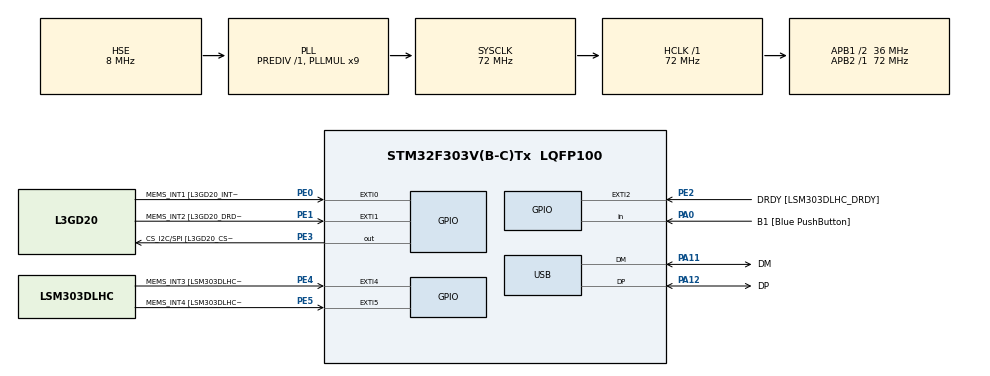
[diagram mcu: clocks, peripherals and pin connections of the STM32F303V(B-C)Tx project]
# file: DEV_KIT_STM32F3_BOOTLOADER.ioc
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Mcu.Family=STM32F3
Mcu.Name=STM32F303V(B-C)Tx
Mcu.Package=LQFP100
NVIC.PriorityGroup=NVIC_PRIORITYGROUP_0
PA0.GPIO_Label=B1 [Blue PushButton]
PA0.Signal=GPIO_Input
PA11.GPIO_Label=DM
PA11.Mode=Device
PA11.Signal=USB_DM
PA12.GPIO_Label=DP
PA12.Mode=Device
PA12.Signal=USB_DP
PA13.GPIO_Label=SWDIO
PA13.Mode=Serial_Wire
PA13.Signal=SYS_JTMS-SWDIO
PA14.GPIO_Label=SWCLK
PA14.Mode=Serial_Wire
PA14.Signal=SYS_JTCK-SWCLK
PA5.GPIO_Label=SPI1_SCK [L3GD20_SCL/SPC]
PA5.Signal=SPI1_SCK
PA6.GPIO_Label=SPI1_MISO [L3GD20_SA0/SDO]
PA6.Signal=SPI1_MISO
PA7.GPIO_Label=SPI1_MISO [L3GD20_SDA/SDI/SDO]
PA7.Signal=SPI1_MOSI
PB3.GPIO_Label=SWO
PB3.Signal=SYS_JTDO-TRACESWO
PB6.GPIO_Label=I2C1_SCL [LSM303DLHC_SCL]
PB6.GPIO_Pu=GPIO_PULLUP
PB6.Signal=I2C1_SCL
PB7.GPIO_Label=I2C1_SDA [LSM303DLHC_SDA]
PB7.GPIO_Pu=GPIO_PULLUP
PB7.Signal=I2C1_SDA
PC14-OSC32_IN.GPIO_Label=OSC32_IN
PC14-OSC32_IN.Signal=RCC_OSC32_IN
PC15-OSC32_OUT.GPIO_Label=OSC32_OUT
PC15-OSC32_OUT.Signal=RCC_OSC32_OUT
PE0.GPIO_Label=MEMS_INT1 [L3GD20_INT1]
PE0.GPIO_ModeDefaultEXTI=GPIO_MODE_EVT_RISING
PE0.Signal=GPXTI0
PE1.GPIO_Label=MEMS_INT2 [L3GD20_DRDY/INT2]
PE1.GPIO_ModeDefaultEXTI=GPIO_MODE_EVT_RISING
PE1.Signal=GPXTI1
PE2.GPIO_Label=DRDY [LSM303DLHC_DRDY]
PE2.GPIO_ModeDefaultEXTI=GPIO_MODE_EVT_RISING
PE2.Signal=GPXTI2
PE3.GPIO_Label=CS_I2C/SPI [L3GD20_CS_I2C/SPI]
PE3.Signal=GPIO_Output
PE4.GPIO_Label=MEMS_INT3 [LSM303DLHC_INT1]
PE4.GPIO_ModeDefaultEXTI=GPIO_MODE_EVT_RISING
PE4.Signal=GPXTI4
PE5.GPIO_Label=MEMS_INT4 [LSM303DLHC_INT2]
PE5.GPIO_ModeDefaultEXTI=GPIO_MODE_EVT_RISING
PE5.Signal=GPXTI5
PF0-OSC_IN.GPIO_Label=OSC_IN
PF0-OSC_IN.Mode=HSE-External-Clock-Source
PF0-OSC_IN.Signal=RCC_OSC_IN
PF1-OSC_OUT.GPIO_Label=OSC_OUT
PF1-OSC_OUT.Signal=RCC_OSC_OUT
ProjectManager.HeapSize=0x200
ProjectManager.StackSize=0x400
ProjectManager.TargetToolchain=STM32CubeIDE
RCC.AHBFreq_Value=72000000
RCC.APB1CLKDivider=RCC_HCLK_DIV2
RCC.APB1Freq_Value=36000000
RCC.APB1TimFreq_Value=72000000
RCC.APB2Freq_Value=72000000
RCC.APB2TimFreq_Value=72000000
RCC.CortexFreq_Value=72000000
RCC.HCLKFreq_Value=72000000
RCC.HSE_VALUE=8000000
RCC.HSI_VALUE=8000000
RCC.LSE_VALUE=32768
RCC.PLLMUL=RCC_PLL_MUL9
RCC.PRESCALERUSB=RCC_USBCLKSOURCE_PLL_DIV1_5
RCC.SYSCLKFreq_VALUE=72000000
RCC.SYSCLKSourceVirtual=RCC_SYSCLKSOURCE_PLLCLK
RCC.USBFreq_Value=48000000
VP_RTC_VS_RTC_Activate.Mode=RTC_Enabled
VP_RTC_VS_RTC_WakeUp_intern.Mode=WakeUp
board=STM32F3DISCOVERY

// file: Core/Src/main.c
/* USER CODE BEGIN Header */
/**
  ******************************************************************************
  * @file           : main.c
  * @brief          : Main program body
  ******************************************************************************
  * @attention
  *
  * Copyright (c) 2023 STMicroelectronics.
  * All rights reserved.
  *
  * This software is licensed under terms that can be found in the LICENSE file
  * in the root directory of this software component.
  * If no LICENSE file comes with this software, it is provided AS-IS.
  *
  ******************************************************************************
  */
/* USER CODE END Header */
#include "main.h"

RTC_HandleTypeDef hrtc;

PCD_HandleTypeDef hpcd_USB_FS;

void SystemClock_Config(void);
static void MX_GPIO_Init(void);

/* USER CODE BEGIN 0 */
void JumpToBootloader(uint32_t ADDR_FLASH_BOOT)
{
	uint32_t appStack;

	typedef void (*pFunction)(void);

	pFunction appEntry;

	appStack = (uint32_t) *((__IO uint32_t*) ADDR_FLASH_BOOT);

	/* Get the application entry point (Second entry in the application vector table) */
	appEntry = (pFunction) *(__IO uint32_t*) (ADDR_FLASH_BOOT + 4);

	/* Reconfigure vector table offset register to match the application location */
	SCB->VTOR = ADDR_FLASH_BOOT;

	/* Set the application stack pointer */
	__set_MSP(appStack);

	/* Start the application */

	appEntry();
}
/* USER CODE END 0 */

int main(void)
{

  /* MCU Configuration--------------------------------------------------------*/

  /* Reset of all peripherals, Initializes the Flash interface and the Systick. */
  HAL_Init();

  /* Configure the system clock */
  SystemClock_Config();

  /* Initialize all configured peripherals */
  MX_GPIO_Init();
  MX_USB_PCD_Init();
  MX_RTC_Init();
  /* USER CODE BEGIN 2 */
  JumpToBootloader(APP_START);
  /* USER CODE END 2 */

  /* Infinite loop */
  while (1)
  {

  }
}

void SystemClock_Config(void)
{
  RCC_OscInitTypeDef RCC_OscInitStruct = {0};
  RCC_ClkInitTypeDef RCC_ClkInitStruct = {0};
  RCC_PeriphCLKInitTypeDef PeriphClkInit = {0};

  /** Initializes the RCC Oscillators according to the specified parameters
  * in the RCC_OscInitTypeDef structure.
  */
  RCC_OscInitStruct.OscillatorType = RCC_OSCILLATORTYPE_LSI|RCC_OSCILLATORTYPE_HSE;
  RCC_OscInitStruct.HSEState = RCC_HSE_BYPASS;
  RCC_OscInitStruct.HSEPredivValue = RCC_HSE_PREDIV_DIV1;
  RCC_OscInitStruct.HSIState = RCC_HSI_ON;
  RCC_OscInitStruct.LSIState = RCC_LSI_ON;
  RCC_OscInitStruct.PLL.PLLState = RCC_PLL_ON;
  RCC_OscInitStruct.PLL.PLLSource = RCC_PLLSOURCE_HSE;
  RCC_OscInitStruct.PLL.PLLMUL = RCC_PLL_MUL9;
  if (HAL_RCC_OscConfig(&RCC_OscInitStruct) != HAL_OK)
  {
    Error_Handler();
  }
  /** Initializes the CPU, AHB and APB buses clocks
  */
  RCC_ClkInitStruct.ClockType = RCC_CLOCKTYPE_HCLK|RCC_CLOCKTYPE_SYSCLK
                              |RCC_CLOCKTYPE_PCLK1|RCC_CLOCKTYPE_PCLK2;
  RCC_ClkInitStruct.SYSCLKSource = RCC_SYSCLKSOURCE_PLLCLK;
  RCC_ClkInitStruct.AHBCLKDivider = RCC_SYSCLK_DIV1;
  RCC_ClkInitStruct.APB1CLKDivider = RCC_HCLK_DIV2;
  RCC_ClkInitStruct.APB2CLKDivider = RCC_HCLK_DIV1;

  if (HAL_RCC_ClockConfig(&RCC_ClkInitStruct, FLASH_LATENCY_2) != HAL_OK)
  {
    Error_Handler();
  }
  PeriphClkInit.PeriphClockSelection = RCC_PERIPHCLK_USB|RCC_PERIPHCLK_RTC;
  PeriphClkInit.RTCClockSelection = RCC_RTCCLKSOURCE_LSI;
  PeriphClkInit.USBClockSelection = RCC_USBCLKSOURCE_PLL_DIV1_5;
  if (HAL_RCCEx_PeriphCLKConfig(&PeriphClkInit) != HAL_OK)
  {
    Error_Handler();
  }
}

void MX_RTC_Init(void)
{

  /** Initialize RTC Only
  */
  hrtc.Instance = RTC;
  hrtc.Init.HourFormat = RTC_HOURFORMAT_24;
  hrtc.Init.AsynchPrediv = 127;
  hrtc.Init.SynchPrediv = 255;
  hrtc.Init.OutPut = RTC_OUTPUT_DISABLE;
  hrtc.Init.OutPutPolarity = RTC_OUTPUT_POLARITY_HIGH;
  hrtc.Init.OutPutType = RTC_OUTPUT_TYPE_OPENDRAIN;
  if (HAL_RTC_Init(&hrtc) != HAL_OK)
  {
    Error_Handler();
  }
  /** Enable the WakeUp
  */
  if (HAL_RTCEx_SetWakeUpTimer(&hrtc, 0, RTC_WAKEUPCLOCK_RTCCLK_DIV16) != HAL_OK)
  {
    Error_Handler();
  }

}

void MX_USB_PCD_Init(void)
{

  hpcd_USB_FS.Instance = USB;
  hpcd_USB_FS.Init.dev_endpoints = 8;
  hpcd_USB_FS.Init.speed = PCD_SPEED_FULL;
  hpcd_USB_FS.Init.phy_itface = PCD_PHY_EMBEDDED;
  hpcd_USB_FS.Init.low_power_enable = DISABLE;
  hpcd_USB_FS.Init.battery_charging_enable = DISABLE;
  if (HAL_PCD_Init(&hpcd_USB_FS) != HAL_OK)
  {
    Error_Handler();
  }

}

static void MX_GPIO_Init(void)
{
  GPIO_InitTypeDef GPIO_InitStruct = {0};

  /* GPIO Ports Clock Enable */
  __HAL_RCC_GPIOE_CLK_ENABLE();
  __HAL_RCC_GPIOC_CLK_ENABLE();
  __HAL_RCC_GPIOF_CLK_ENABLE();
  __HAL_RCC_GPIOA_CLK_ENABLE();
  __HAL_RCC_GPIOB_CLK_ENABLE();

  /*Configure GPIO pin Output Level */
  HAL_GPIO_WritePin(CS_I2C_SPI_GPIO_Port, CS_I2C_SPI_Pin, GPIO_PIN_RESET);

  /*Configure GPIO pins : DRDY_Pin MEMS_INT3_Pin MEMS_INT4_Pin MEMS_INT1_Pin
                           MEMS_INT2_Pin */
  GPIO_InitStruct.Pin = DRDY_Pin|MEMS_INT3_Pin|MEMS_INT4_Pin|MEMS_INT1_Pin
                          |MEMS_INT2_Pin;
  GPIO_InitStruct.Mode = GPIO_MODE_EVT_RISING;
  GPIO_InitStruct.Pull = GPIO_NOPULL;
  HAL_GPIO_Init(GPIOE, &GPIO_InitStruct);

  /*Configure GPIO pin : CS_I2C_SPI_Pin */
  GPIO_InitStruct.Pin = CS_I2C_SPI_Pin;
  GPIO_InitStruct.Mode = GPIO_MODE_OUTPUT_PP;
  GPIO_InitStruct.Pull = GPIO_NOPULL;
  GPIO_InitStruct.Speed = GPIO_SPEED_FREQ_LOW;
  HAL_GPIO_Init(CS_I2C_SPI_GPIO_Port, &GPIO_InitStruct);

  /*Configure GPIO pin : B1_Pin */
  GPIO_InitStruct.Pin = B1_Pin;
  GPIO_InitStruct.Mode = GPIO_MODE_INPUT;
  GPIO_InitStruct.Pull = GPIO_NOPULL;
  HAL_GPIO_Init(B1_GPIO_Port, &GPIO_InitStruct);

  /*Configure GPIO pins : SPI1_SCK_Pin SPI1_MISO_Pin SPI1_MISOA7_Pin */
  GPIO_InitStruct.Pin = SPI1_SCK_Pin|SPI1_MISO_Pin|SPI1_MISOA7_Pin;
  GPIO_InitStruct.Mode = GPIO_MODE_AF_PP;
  GPIO_InitStruct.Pull = GPIO_NOPULL;
  GPIO_InitStruct.Speed = GPIO_SPEED_FREQ_HIGH;
  GPIO_InitStruct.Alternate = GPIO_AF5_SPI1;
  HAL_GPIO_Init(GPIOA, &GPIO_InitStruct);

  /*Configure GPIO pins : I2C1_SCL_Pin I2C1_SDA_Pin */
  GPIO_InitStruct.Pin = I2C1_SCL_Pin|I2C1_SDA_Pin;
  GPIO_InitStruct.Mode = GPIO_MODE_AF_OD;
  GPIO_InitStruct.Pull = GPIO_PULLUP;
  GPIO_InitStruct.Speed = GPIO_SPEED_FREQ_HIGH;
  GPIO_InitStruct.Alternate = GPIO_AF4_I2C1;
  HAL_GPIO_Init(GPIOB, &GPIO_InitStruct);

}

void Error_Handler(void)
{
  __disable_irq();
  while (1)
  {
  }
}
